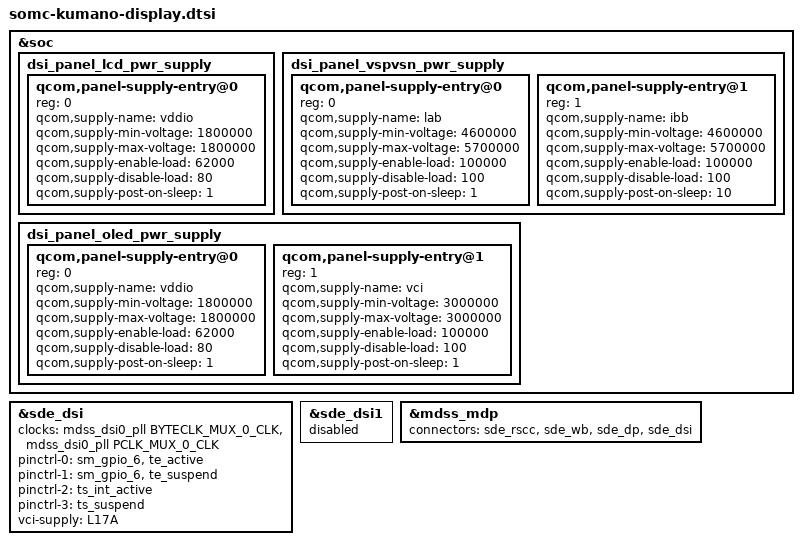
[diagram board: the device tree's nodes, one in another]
// SPDX-License-Identifier: GPL-2.0-only
/*
 * Copyright (c) 2017-2018, The Linux Foundation. All rights reserved.
 */

&soc {
	dsi_panel_lcd_pwr_supply: dsi_panel_lcd_pwr_supply {
		#address-cells = <1>;
		#size-cells = <0>;

		qcom,panel-supply-entry@0 {
			reg = <0>;
			qcom,supply-name = "vddio";
			qcom,supply-min-voltage = <1800000>;
			qcom,supply-max-voltage = <1800000>;
			qcom,supply-enable-load = <62000>;
			qcom,supply-disable-load = <80>;
			qcom,supply-post-on-sleep = <1>;
		};
	};

	dsi_panel_vspvsn_pwr_supply: dsi_panel_vspvsn_pwr_supply {
		#address-cells = <1>;
		#size-cells = <0>;

		qcom,panel-supply-entry@0 {
			reg = <0>;
			qcom,supply-name = "lab";
			qcom,supply-min-voltage = <4600000>;
			qcom,supply-max-voltage = <5700000>;
			qcom,supply-enable-load = <100000>;
			qcom,supply-disable-load = <100>;
			qcom,supply-post-on-sleep = <1>;
		};

		qcom,panel-supply-entry@1 {
			reg = <1>;
			qcom,supply-name = "ibb";
			qcom,supply-min-voltage = <4600000>;
			qcom,supply-max-voltage = <5700000>;
			qcom,supply-enable-load = <100000>;
			qcom,supply-disable-load = <100>;
			qcom,supply-post-on-sleep = <10>;
		};
	};

	dsi_panel_oled_pwr_supply: dsi_panel_oled_pwr_supply {
		#address-cells = <1>;
		#size-cells = <0>;

		qcom,panel-supply-entry@0 {
			reg = <0>;
			qcom,supply-name = "vddio";
			qcom,supply-min-voltage = <1800000>;
			qcom,supply-max-voltage = <1800000>;
			qcom,supply-enable-load = <62000>;
			qcom,supply-disable-load = <80>;
			qcom,supply-post-on-sleep = <1>;
		};

		qcom,panel-supply-entry@1 {
			reg = <1>;
			qcom,supply-name = "vci";
			qcom,supply-min-voltage = <3000000>;
			qcom,supply-max-voltage = <3000000>;
			qcom,supply-enable-load = <100000>;
			qcom,supply-disable-load = <100>;
			qcom,supply-post-on-sleep = <1>;
		};
	};
};

&sde_dsi {
	clocks = <&mdss_dsi0_pll BYTECLK_MUX_0_CLK>,
		 <&mdss_dsi0_pll PCLK_MUX_0_CLK>;
	clock-names = "mux_byte_clk0", "mux_pixel_clk0";

	pinctrl-names = "panel_active", "panel_suspend",
			"somc_ts_int_active", "somc_ts_int_suspend";
	pinctrl-0 = <&sm_gpio_6 &te_active>;
	pinctrl-1 = <&sm_gpio_6 &te_suspend>;
	pinctrl-2 = <&ts_int_active>;
	pinctrl-3 = <&ts_suspend>;

	/delete-property/ vdd-supply;
	vci-supply = <&L17A>;
};

&sde_dsi1 {
	status = "disabled";
};

&mdss_mdp {
	connectors = <&sde_rscc &sde_wb &sde_dp &sde_dsi>;
};
